# STM32H725 register map
File version: 2.0
CPU: CM7 r0p1, little endian, MPU, FPU, 4 interrupt priority bits
Registers are 32-bit, read-write, reset 0x0 unless marked. A register's access mark holds for its fields unless they carry their own. Offsets are from the block's base; [hi:lo] are bit positions.

## ADC12_Common — Analog-to-Digital Converter
Base 0x40022300
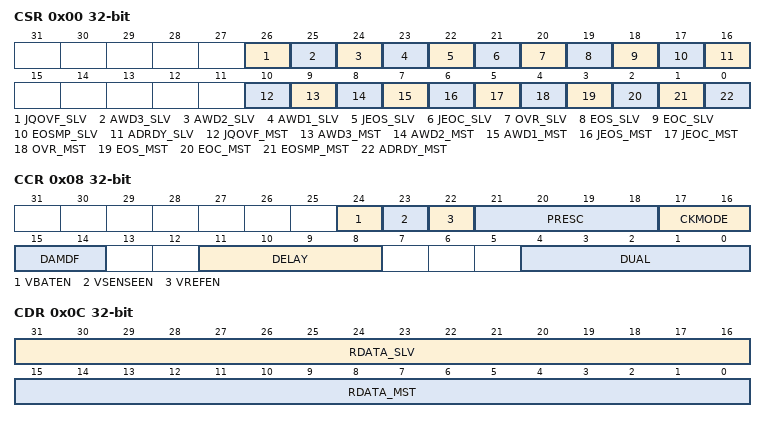
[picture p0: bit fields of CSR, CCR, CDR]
0x00 CSR ro — ADC Common status register
  [26] JQOVF_SLV — Injected Context Queue Overflow flag of the slave ADC
  [25] AWD3_SLV — Analog watchdog 3 flag of the slave ADC
  [24] AWD2_SLV — Analog watchdog 2 flag of the slave ADC
  [23] AWD1_SLV — Analog watchdog 1 flag of the slave ADC
  [22] JEOS_SLV — End of injected sequence flag of the slave ADC
  [21] JEOC_SLV — End of injected conversion flag of the slave ADC
  [20] OVR_SLV — Overrun flag of the slave ADC
  [19] EOS_SLV — End of regular sequence flag of the slave ADC
  [18] EOC_SLV — End of regular conversion of the slave ADC
  [17] EOSMP_SLV — End of Sampling phase flag of the slave ADC
  [16] ADRDY_SLV — Slave ADC ready
  [10] JQOVF_MST — Injected Context Queue Overflow flag of the master ADC
  [9] AWD3_MST — Analog watchdog 3 flag of the master ADC
  [8] AWD2_MST — Analog watchdog 2 flag of the master ADC
  [7] AWD1_MST — Analog watchdog 1 flag of the master ADC
  [6] JEOS_MST — End of injected sequence flag of the master ADC
  [5] JEOC_MST — End of injected conversion flag of the master ADC
  [4] OVR_MST — Overrun flag of the master ADC
  [3] EOS_MST — End of regular sequence flag of the master ADC
  [2] EOC_MST — End of regular conversion of the master ADC
  [1] EOSMP_MST — End of Sampling phase flag of the master ADC
  [0] ADRDY_MST — Master ADC ready
0x08 CCR — ADC common control register
  [24] VBATEN — VBAT enable
  [23] VSENSEEN — Temperature sensor enable
  [22] VREFEN — VREFINT enable
  [21:18] PRESC — ADC prescaler
  [17:16] CKMODE — ADC clock mode
  [15:14] DAMDF — Dual ADC Mode Data Format
  [11:8] DELAY — Delay between 2 sampling phases
  [4:0] DUAL — Dual ADC mode selection
0x0C CDR ro — ADC common regular data register for dual and triple modes
  [31:16] RDATA_SLV — Regular data of the slave ADC
  [15:0] RDATA_MST — Regular data of the master ADC
0x10 CDR2 ro — ADC x common regular data register for 32-bit dual mode
  [31:0] RDATA_ALT — Regular data of the master/slave alternated ADCs

## ADC3_Common — Analog-to-Digital Converter
Base 0x58026300
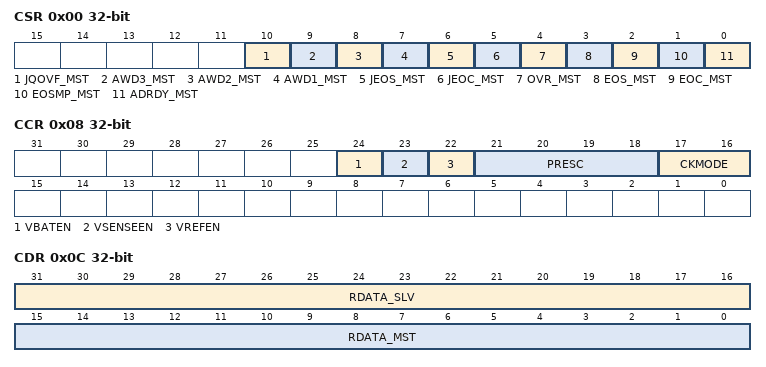
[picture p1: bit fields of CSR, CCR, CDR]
0x00 CSR ro — ADC common status register
  [10] JQOVF_MST — Injected Context Queue Overflow flag of the master ADC This bit is a copy of the JQOVF bit in the corresponding ADC_ISR register.
  [9] AWD3_MST — Analog watchdog 3 flag of the master ADC This bit is a copy of the AWD3 bit in the corresponding ADC_ISR register.
  [8] AWD2_MST — Analog watchdog 2 flag of the master ADC This bit is a copy of the AWD2 bit in the corresponding ADC_ISR register.
  [7] AWD1_MST — Analog watchdog 1 flag of the master ADC This bit is a copy of the AWD1 bit in the corresponding ADC_ISR register.
  [6] JEOS_MST — End of injected sequence flag of the master ADC This bit is a copy of the JEOS bit in the corresponding ADC_ISR register.
  [5] JEOC_MST — End of injected conversion flag of the master ADC This bit is a copy of the JEOC bit in the corresponding ADC_ISR register.
  [4] OVR_MST — Overrun flag of the master ADC This bit is a copy of the OVR bit in the corresponding ADC_ISR register.
  [3] EOS_MST — End of regular sequence flag of the master ADC This bit is a copy of the EOS bit in the corresponding ADC_ISR register.
  [2] EOC_MST — End of regular conversion of the master ADC This bit is a copy of the EOC bit in the corresponding ADC_ISR register.
  [1] EOSMP_MST — End of Sampling phase flag of the master ADC This bit is a copy of the EOSMP bit in the corresponding ADC_ISR register.
  [0] ADRDY_MST — Master ADC ready This bit is a copy of the ADRDY bit in the corresponding ADC_ISR register.
0x08 CCR — ADC common control register
  [24] VBATEN — VBAT enable This bit is set and cleared by software to control.
  [23] VSENSEEN — VSENSE enable This bit is set and cleared by software to control VSENSE.
  [22] VREFEN — VREFINT enable This bit is set and cleared by software to enable/disable the VREFINT channel.
  [21:18] PRESC — ADC prescaler These bits are set and cleared by software to select the frequency of the clock to the ADC. The clock is common for all the ADCs. other: reserved Note: The software is allowed to write these bits only when the ADC is disabled (ADCAL = 0, JADSTART = 0, ADSTART = 0, ADSTP = 0, ADDIS = 0 and ADEN = 0). The ADC prescaler value is applied only when CKMODE[1:0] = 0b00.
  [17:16] CKMODE — ADC clock mode These bits are set and cleared by software to define the ADC clock scheme (which is common to both master and slave ADCs): In all synchronous clock modes, there is no jitter in the delay from a timer trigger to the start of a conversion. Note: The software is allowed to write these bits only when the ADCs are disabled (ADCAL = 0, JADSTART = 0, ADSTART = 0, ADSTP = 0, ADDIS = 0 and ADEN = 0).
0x0C CDR ro — ADC common regular data register for dual and triple modes
  [31:16] RDATA_SLV — Regular data of the slave ADC
  [15:0] RDATA_MST — Regular data of the master ADC
0x10 CDR2 ro — ADC x common regular data register for 32-bit dual mode
  [31:0] RDATA_ALT — Regular data of the master/slave alternated ADCs
